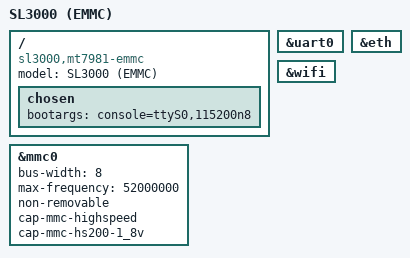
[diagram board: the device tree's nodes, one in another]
// SPDX-License-Identifier: GPL-2.0-or-later OR MIT
/dts-v1/;

#include "mt7981.dtsi"

/ {
	model = "SL3000 (EMMC)";
	compatible = "sl3000,mt7981-emmc", "mediatek,mt7981";

	chosen {
		bootargs = "console=ttyS0,115200n8";
	};
};

&uart0 {
	status = "okay";
};

&eth {
	status = "okay";
};

&wifi {
	status = "okay";
};

&mmc0 {
	status = "okay";
	bus-width = <8>;
	max-frequency = <52000000>;
	non-removable;
	cap-mmc-highspeed;
	cap-mmc-hs200-1_8v;
};
